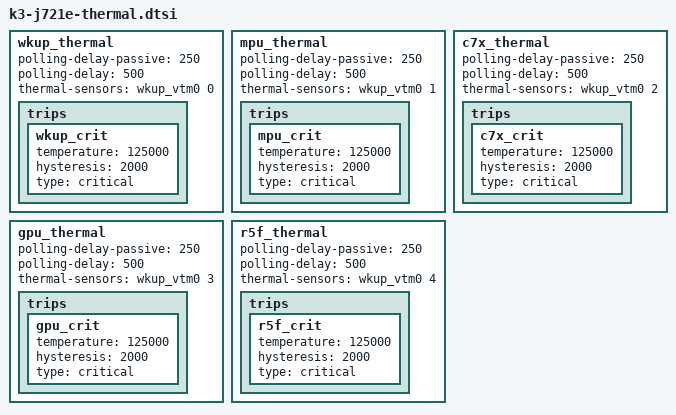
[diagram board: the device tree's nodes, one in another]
// SPDX-License-Identifier: GPL-2.0

#include <dt-bindings/thermal/thermal.h>

wkup_thermal: wkup_thermal {
	polling-delay-passive = <250>; /* milliseconds */
	polling-delay = <500>; /* milliseconds */
	thermal-sensors = <&wkup_vtm0 0>;

	trips {
		wkup_crit: wkup_crit {
			temperature = <125000>; /* milliCelsius */
			hysteresis = <2000>; /* milliCelsius */
			type = "critical";
		};
	};
};

mpu_thermal: mpu_thermal {
	polling-delay-passive = <250>; /* milliseconds */
	polling-delay = <500>; /* milliseconds */
	thermal-sensors = <&wkup_vtm0 1>;

	trips {
		mpu_crit: mpu_crit {
			temperature = <125000>; /* milliCelsius */
			hysteresis = <2000>; /* milliCelsius */
			type = "critical";
		};
	};
};

c7x_thermal: c7x_thermal {
	polling-delay-passive = <250>; /* milliseconds */
	polling-delay = <500>; /* milliseconds */
	thermal-sensors = <&wkup_vtm0 2>;

	trips {
		c7x_crit: c7x_crit {
			temperature = <125000>; /* milliCelsius */
			hysteresis = <2000>; /* milliCelsius */
			type = "critical";
		};
	};
};

gpu_thermal: gpu_thermal {
	polling-delay-passive = <250>; /* milliseconds */
	polling-delay = <500>; /* milliseconds */
	thermal-sensors = <&wkup_vtm0 3>;

	trips {
		gpu_crit: gpu_crit {
			temperature = <125000>; /* milliCelsius */
			hysteresis = <2000>; /* milliCelsius */
			type = "critical";
		};
	};
};

r5f_thermal: r5f_thermal {
	polling-delay-passive = <250>; /* milliseconds */
	polling-delay = <500>; /* milliseconds */
	thermal-sensors = <&wkup_vtm0 4>;

	trips {
		r5f_crit: r5f_crit {
			temperature = <125000>; /* milliCelsius */
			hysteresis = <2000>; /* milliCelsius */
			type = "critical";
		};
	};
};
